# RP2040 register map
Vendor: Raspberry Pi; Series: RP; File version: 0.1
Dual-core Arm Cortex-M0+ processor, flexible clock running up to 133 MHz 264KB on-chip SRAM 2 x UART, 2 x SPI controllers, 2 x I2C controllers, 16 x PWM channels 1 x USB 1.1 controller and PHY, with host and device support 8 x Programmable I/O (PIO) state machines for custom peripheral support Supported input power 1.8-5.5V DC Operating temperature -20C to +85C Drag-and-drop programming using mass storage over USB Low-power sleep and dormant modes Accurate on-chip clock Temperature sensor Accelerated integer and floating-point libraries on-chip
CPU: CM0PLUS r0p1, little endian, MPU, no FPU, VTOR, 2 interrupt priority bits, 32 interrupts
Registers are 32-bit, read-write, reset 0x0 unless marked. A register's access mark holds for its fields unless they carry their own. Offsets are from the block's base; lines under a group give offsets from that group; [hi:lo] are bit positions; {n}, {i} and the like mark numbered series; 'fields as' and 'values as' point back to an identical list; <NAME> marks a mode.

## Memory map
0x40000000 SYSINFO size 0x44
0x40028000 PLL_SYS size 0x10
0x4002C000 PLL_USB size 0x10
0x4006C000 TBMAN size 0x4 — Testbench manager. Allows the programmer to know what platform their software is running on.

## PLL_SYS
Base 0x40028000
Same registers: PLL_USB 0x4002C000
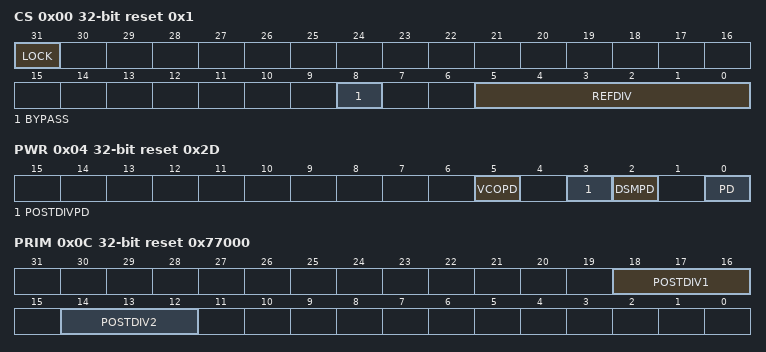
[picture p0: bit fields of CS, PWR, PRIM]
0x00 CS reset 0x1 — Control and Status GENERAL CONSTRAINTS: Reference clock frequency min=5MHz, max=800MHz Feedback divider min=16, max=320 VCO frequency min=750MHz, max=1600MHz
  [31] LOCK ro — PLL is locked
  [8] BYPASS — Passes the reference clock to the output instead of the divided VCO. The VCO continues to run so the user can switch between the reference clock and the divided VCO but the output will glitch when doing so.
  [5:0] REFDIV — Divides the PLL input reference clock. Behaviour is undefined for div=0. PLL output will be unpredictable during refdiv changes, wait for lock=1 before using it.
0x04 PWR reset 0x2D — Controls the PLL power modes.
  [5] VCOPD — PLL VCO powerdown To save power set high when PLL output not required or bypass=1.
  [3] POSTDIVPD — PLL post divider powerdown To save power set high when PLL output not required or bypass=1.
  [2] DSMPD — PLL DSM powerdown Nothing is achieved by setting this low.
  [0] PD — PLL powerdown To save power set high when PLL output not required.
0x08 FBDIV_INT — Feedback divisor (note: this PLL does not support fractional division)
  [11:0] FBDIV_INT — see ctrl reg description for constraints
0x0C PRIM reset 0x77000 — Controls the PLL post dividers for the primary output (note: this PLL does not have a secondary output) the primary output is driven from VCO divided by postdiv1*postdiv2
  [18:16] POSTDIV1 — divide by 1-7
  [14:12] POSTDIV2 — divide by 1-7

## SYSINFO
Base 0x40000000
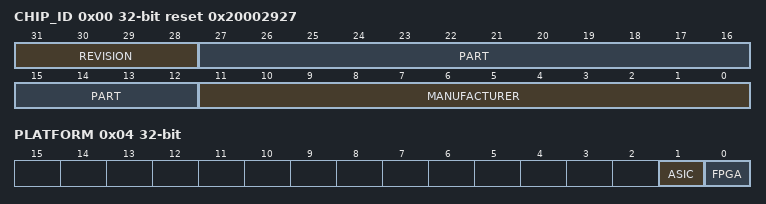
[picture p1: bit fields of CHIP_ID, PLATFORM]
0x00 CHIP_ID reset 0x20002927 — JEDEC JEP-106 compliant chip identifier.
  [31:28] REVISION ro, [27:12] PART ro, [11:0] MANUFACTURER ro
0x04 PLATFORM — Platform register. Allows software to know what environment it is running in.
  [1] ASIC ro, [0] FPGA ro
0x40 GITREF_RP2040 reset not defined — Git hash of the chip source. Used to identify chip version.
  [31:0] GITREF_RP2040 ro

## TBMAN — Testbench manager. Allows the programmer to know what platform their software is running on.
Base 0x4006C000
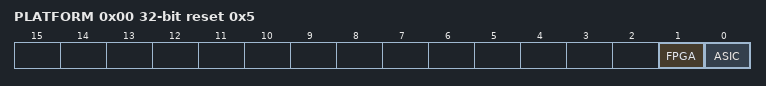
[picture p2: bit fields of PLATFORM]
0x00 PLATFORM reset 0x5 — Indicates the type of platform in use
  [1] FPGA ro — Indicates the platform is an FPGA
  [0] ASIC ro — Indicates the platform is an ASIC

## Licence text in the file
Copyright (c) 2021 Raspberry Pi Ltd. SPDX-License-Identifier: BSD-3-Clause

## Notices in the file
Real vendor SVD subset: upstream blob 4c4e249ca06f6c5750c7bf5d3dd40eeb7ecab24e; source license preserved
